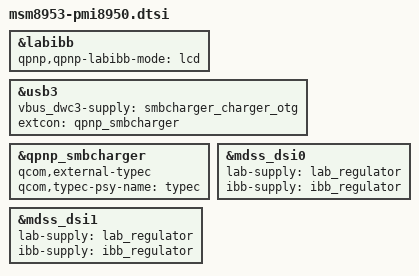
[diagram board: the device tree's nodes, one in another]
/*
 * Copyright (c) 2017-2018, The Linux Foundation. All rights reserved.
 *
 * This program is free software; you can redistribute it and/or modify
 * it under the terms of the GNU General Public License version 2 and
 * only version 2 as published by the Free Software Foundation.
 *
 * This program is distributed in the hope that it will be useful,
 * but WITHOUT ANY WARRANTY; without even the implied warranty of
 * MERCHANTABILITY or FITNESS FOR A PARTICULAR PURPOSE.  See the
 * GNU General Public License for more details.
 */

&labibb {
	status = "ok";
	qpnp,qpnp-labibb-mode = "lcd";
};

&usb3 {
	vbus_dwc3-supply = <&smbcharger_charger_otg>;
	extcon = <&qpnp_smbcharger>;
};

&qpnp_smbcharger {
	qcom,external-typec;
	qcom,typec-psy-name = "typec";
};

&mdss_dsi0 {
	lab-supply = <&lab_regulator>;
	ibb-supply = <&ibb_regulator>;
};

&mdss_dsi1 {
	lab-supply = <&lab_regulator>;
	ibb-supply = <&ibb_regulator>;
};
